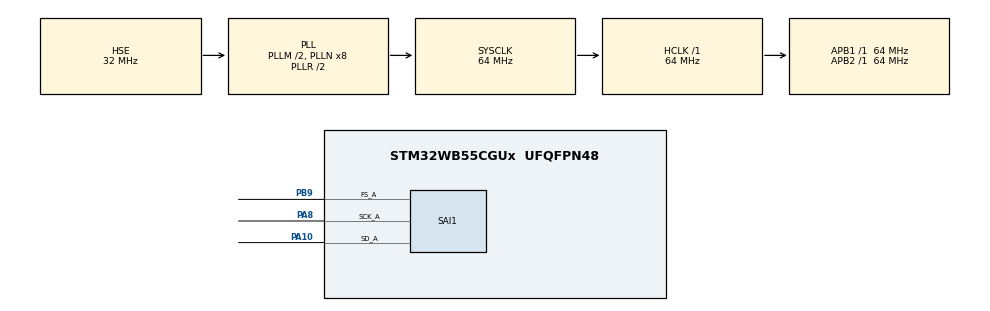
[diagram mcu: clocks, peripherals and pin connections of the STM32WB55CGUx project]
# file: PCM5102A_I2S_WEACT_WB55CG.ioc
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Dma.Request0=SAI1_A
Dma.SAI1_A.0.Direction=DMA_MEMORY_TO_PERIPH
Dma.SAI1_A.0.EventEnable=DISABLE
Dma.SAI1_A.0.Instance=DMA1_Channel1
Dma.SAI1_A.0.MemDataAlignment=DMA_MDATAALIGN_WORD
Dma.SAI1_A.0.MemInc=DMA_MINC_ENABLE
Dma.SAI1_A.0.Mode=DMA_CIRCULAR
Dma.SAI1_A.0.PeriphDataAlignment=DMA_PDATAALIGN_WORD
Dma.SAI1_A.0.PeriphInc=DMA_PINC_DISABLE
Dma.SAI1_A.0.Polarity=HAL_DMAMUX_REQ_GEN_RISING
Dma.SAI1_A.0.Priority=DMA_PRIORITY_HIGH
Dma.SAI1_A.0.RequestNumber=1
Dma.SAI1_A.0.SignalID=NONE
Dma.SAI1_A.0.SyncEnable=DISABLE
Dma.SAI1_A.0.SyncPolarity=HAL_DMAMUX_SYNC_NO_EVENT
Dma.SAI1_A.0.SyncRequestNumber=1
Dma.SAI1_A.0.SyncSignalID=NONE
Mcu.Family=STM32WB
Mcu.Name=STM32WB55CGUx
Mcu.Package=UFQFPN48
NVIC.DMA1_Channel1_IRQn=true\:0\:0\:false\:false\:true\:false\:true\:true
NVIC.PriorityGroup=NVIC_PRIORITYGROUP_4
OSC_IN.Mode=HSE-External-Oscillator
OSC_IN.Signal=RCC_OSC_IN
OSC_OUT.Mode=HSE-External-Oscillator
OSC_OUT.Signal=RCC_OSC_OUT
PA10.Mode=SAI_A_Master
PA10.Signal=SAI1_SD_A
PA8.Mode=SAI_A_Master
PA8.Signal=SAI1_SCK_A
PB9.Mode=SAI_A_Master
PB9.Signal=SAI1_FS_A
ProjectManager.HeapSize=0x200
ProjectManager.StackSize=0x400
ProjectManager.TargetToolchain=STM32CubeIDE
RCC.ADCFreq_Value=64000000
RCC.AHB2CLKDivider=RCC_SYSCLK_DIV2
RCC.AHBFreq_Value=64000000
RCC.APB1Freq_Value=64000000
RCC.APB1TimFreq_Value=64000000
RCC.APB2Freq_Value=64000000
RCC.APB2TimFreq_Value=64000000
RCC.APB3Freq_Value=16000000
RCC.Cortex2_Div=SYSTICK_CLKSOURCE_HCLK_DIV8
RCC.CortexFreq_Value=64000000
RCC.HCLKFreq_Value=64000000
RCC.HSE_VALUE=32000000
RCC.HSI48_VALUE=48000000
RCC.HSI_VALUE=16000000
RCC.LSE_VALUE=32768
RCC.PLLM=RCC_PLLM_DIV2
RCC.PLLSourceVirtual=RCC_PLLSOURCE_HSE
RCC.SYSCLKFreq_VALUE=64000000
RCC.SYSCLKSource=RCC_SYSCLKSOURCE_PLLCLK
RCC.USBFreq_Value=64000000
RCC.VCOOutputFreq_Value=128000000
SAI1.AudioFrequency-SAI_A_Master=SAI_AUDIO_FREQUENCY_16K
SAI1.BasicDataSize-SAI_A_Master=SAI_PROTOCOL_DATASIZE_32BIT
SAI1.ErrorAudioFreq-SAI_A_Master=-2.34 %
SAI1.FIFOThreshold-SAI_A_Master=SAI_FIFOTHRESHOLD_HF
SAI1.InitProtocol-SAI_A_Master=Enable
SAI1.Instance-SAI_A_Master=SAI$Index_Block_A
SAI1.MClockEnable-SAI_A_Master=SAI_MASTERCLOCK_DISABLE
SAI1.NoDivider-SAI_A_Master=SAI_MASTERDIVIDER_DISABLE
SAI1.OutputDrive-SAI_A_Master=SAI_OUTPUTDRIVE_ENABLE
SAI1.RealAudioFreq-SAI_A_Master=250.0 KHz
SAI1.VirtualMode-SAI_A_Master=VM_MASTER
SAI1.VirtualProtocol-SAI_A_BASIC=VM_BASIC_PROTOCOL
VP_MEMORYMAP_VS_MEMORYMAP.Mode=CurAppReg
VP_SAI1_VP_$IpInstance_SAIA_SAI_BASIC.Mode=SAI_A_BASIC
board=custom

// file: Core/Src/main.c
/* USER CODE BEGIN Header */
/**
  ******************************************************************************
  * @file           : main.c
  * @brief          : Main program body
  ******************************************************************************
  * @attention
  *
  * Copyright (c) 2026 STMicroelectronics.
  * All rights reserved.
  *
  * This software is licensed under terms that can be found in the LICENSE file
  * in the root directory of this software component.
  * If no LICENSE file comes with this software, it is provided AS-IS.
  *
  ******************************************************************************
  */
/* USER CODE END Header */
#include "main.h"

/* USER CODE BEGIN Includes */
#include <math.h>
/* USER CODE END Includes */

/* USER CODE BEGIN PD */
#define SAMPLE_RATE         16000
#define TONE_FREQ            2000
#define AUDIO_CHANNELS          2

#define SAMPLES_PER_PERIOD  (SAMPLE_RATE / TONE_FREQ)
#define SAMPLES_PER_HALF    (SAMPLES_PER_PERIOD / 2)
#define DMA_SAMPLES         (SAMPLES_PER_PERIOD * AUDIO_CHANNELS)
/* USER CODE END PD */

SAI_HandleTypeDef hsai_BlockA1;
DMA_HandleTypeDef hdma_sai1_a;

void SystemClock_Config(void);
void PeriphCommonClock_Config(void);
static void MX_GPIO_Init(void);
static void MX_DMA_Init(void);
static void MX_SAI1_Init(void);

int main(void)
{

  /* MCU Configuration--------------------------------------------------------*/

  /* Reset of all peripherals, Initializes the Flash interface and the Systick. */
  HAL_Init();

  /* Configure the system clock */
  SystemClock_Config();

  /* Configure the peripherals common clocks */
  PeriphCommonClock_Config();

  /* Initialize all configured peripherals */
  MX_GPIO_Init();
  MX_DMA_Init();
  MX_SAI1_Init();
  /* USER CODE BEGIN 2 */
  uint8_t volume = 5;      // 0..100
  const int32_t max_amp = 0x60000000;

  int32_t amplitude = (max_amp * volume) / 100;
  int32_t tx[DMA_SAMPLES];

  for (int i = 0; i < SAMPLES_PER_PERIOD; i++)
  {
      int32_t sample = ((i / SAMPLES_PER_HALF) & 1) ?
    		  	  	  	  amplitude :
						  -amplitude;

      tx[i * AUDIO_CHANNELS + 0] = sample;   // Left
      tx[i * AUDIO_CHANNELS + 1] = sample;   // Right
  }

  HAL_SAI_Transmit_DMA(
      &hsai_BlockA1,
      (uint8_t *)tx,
      DMA_SAMPLES
  );
  /* USER CODE END 2 */

  /* Infinite loop */
  while (1)
  {

  }
}

void SystemClock_Config(void)
{
  RCC_OscInitTypeDef RCC_OscInitStruct = {0};
  RCC_ClkInitTypeDef RCC_ClkInitStruct = {0};

  /** Configure the main internal regulator output voltage
  */
  __HAL_PWR_VOLTAGESCALING_CONFIG(PWR_REGULATOR_VOLTAGE_SCALE1);

  /** Initializes the RCC Oscillators according to the specified parameters
  * in the RCC_OscInitTypeDef structure.
  */
  RCC_OscInitStruct.OscillatorType = RCC_OSCILLATORTYPE_HSI|RCC_OSCILLATORTYPE_HSE;
  RCC_OscInitStruct.HSEState = RCC_HSE_ON;
  RCC_OscInitStruct.HSIState = RCC_HSI_ON;
  RCC_OscInitStruct.HSICalibrationValue = RCC_HSICALIBRATION_DEFAULT;
  RCC_OscInitStruct.PLL.PLLState = RCC_PLL_ON;
  RCC_OscInitStruct.PLL.PLLSource = RCC_PLLSOURCE_HSE;
  RCC_OscInitStruct.PLL.PLLM = RCC_PLLM_DIV2;
  RCC_OscInitStruct.PLL.PLLN = 8;
  RCC_OscInitStruct.PLL.PLLP = RCC_PLLP_DIV2;
  RCC_OscInitStruct.PLL.PLLR = RCC_PLLR_DIV2;
  RCC_OscInitStruct.PLL.PLLQ = RCC_PLLQ_DIV2;
  if (HAL_RCC_OscConfig(&RCC_OscInitStruct) != HAL_OK)
  {
    Error_Handler();
  }

  /** Configure the SYSCLKSource, HCLK, PCLK1 and PCLK2 clocks dividers
  */
  RCC_ClkInitStruct.ClockType = RCC_CLOCKTYPE_HCLK4|RCC_CLOCKTYPE_HCLK2
                              |RCC_CLOCKTYPE_HCLK|RCC_CLOCKTYPE_SYSCLK
                              |RCC_CLOCKTYPE_PCLK1|RCC_CLOCKTYPE_PCLK2;
  RCC_ClkInitStruct.SYSCLKSource = RCC_SYSCLKSOURCE_PLLCLK;
  RCC_ClkInitStruct.AHBCLKDivider = RCC_SYSCLK_DIV1;
  RCC_ClkInitStruct.APB1CLKDivider = RCC_HCLK_DIV1;
  RCC_ClkInitStruct.APB2CLKDivider = RCC_HCLK_DIV1;
  RCC_ClkInitStruct.AHBCLK2Divider = RCC_SYSCLK_DIV2;
  RCC_ClkInitStruct.AHBCLK4Divider = RCC_SYSCLK_DIV1;

  if (HAL_RCC_ClockConfig(&RCC_ClkInitStruct, FLASH_LATENCY_3) != HAL_OK)
  {
    Error_Handler();
  }
}

void PeriphCommonClock_Config(void)
{
  RCC_PeriphCLKInitTypeDef PeriphClkInitStruct = {0};

  /** Initializes the peripherals clock
  */
  PeriphClkInitStruct.PeriphClockSelection = RCC_PERIPHCLK_SMPS;
  PeriphClkInitStruct.SmpsClockSelection = RCC_SMPSCLKSOURCE_HSI;
  PeriphClkInitStruct.SmpsDivSelection = RCC_SMPSCLKDIV_RANGE1;

  if (HAL_RCCEx_PeriphCLKConfig(&PeriphClkInitStruct) != HAL_OK)
  {
    Error_Handler();
  }
}

static void MX_SAI1_Init(void)
{

  hsai_BlockA1.Instance = SAI1_Block_A;
  hsai_BlockA1.Init.AudioMode = SAI_MODEMASTER_TX;
  hsai_BlockA1.Init.Synchro = SAI_ASYNCHRONOUS;
  hsai_BlockA1.Init.OutputDrive = SAI_OUTPUTDRIVE_ENABLE;
  hsai_BlockA1.Init.NoDivider = SAI_MASTERDIVIDER_DISABLE;
  hsai_BlockA1.Init.MckOverSampling = SAI_MCK_OVERSAMPLING_DISABLE;
  hsai_BlockA1.Init.FIFOThreshold = SAI_FIFOTHRESHOLD_HF;
  hsai_BlockA1.Init.AudioFrequency = SAI_AUDIO_FREQUENCY_16K;
  hsai_BlockA1.Init.SynchroExt = SAI_SYNCEXT_DISABLE;
  hsai_BlockA1.Init.MonoStereoMode = SAI_STEREOMODE;
  hsai_BlockA1.Init.CompandingMode = SAI_NOCOMPANDING;
  hsai_BlockA1.Init.TriState = SAI_OUTPUT_NOTRELEASED;
  if (HAL_SAI_InitProtocol(&hsai_BlockA1, SAI_I2S_STANDARD, SAI_PROTOCOL_DATASIZE_32BIT, 2) != HAL_OK)
  {
    Error_Handler();
  }

}

static void MX_DMA_Init(void)
{

  /* DMA controller clock enable */
  __HAL_RCC_DMAMUX1_CLK_ENABLE();
  __HAL_RCC_DMA1_CLK_ENABLE();

  /* DMA interrupt init */
  /* DMA1_Channel1_IRQn interrupt configuration */
  HAL_NVIC_SetPriority(DMA1_Channel1_IRQn, 0, 0);
  HAL_NVIC_EnableIRQ(DMA1_Channel1_IRQn);

}

static void MX_GPIO_Init(void)
{

  /* GPIO Ports Clock Enable */
  __HAL_RCC_GPIOB_CLK_ENABLE();
  __HAL_RCC_GPIOA_CLK_ENABLE();

}

void Error_Handler(void)
{
  __disable_irq();
  while (1)
  {
  }
}
